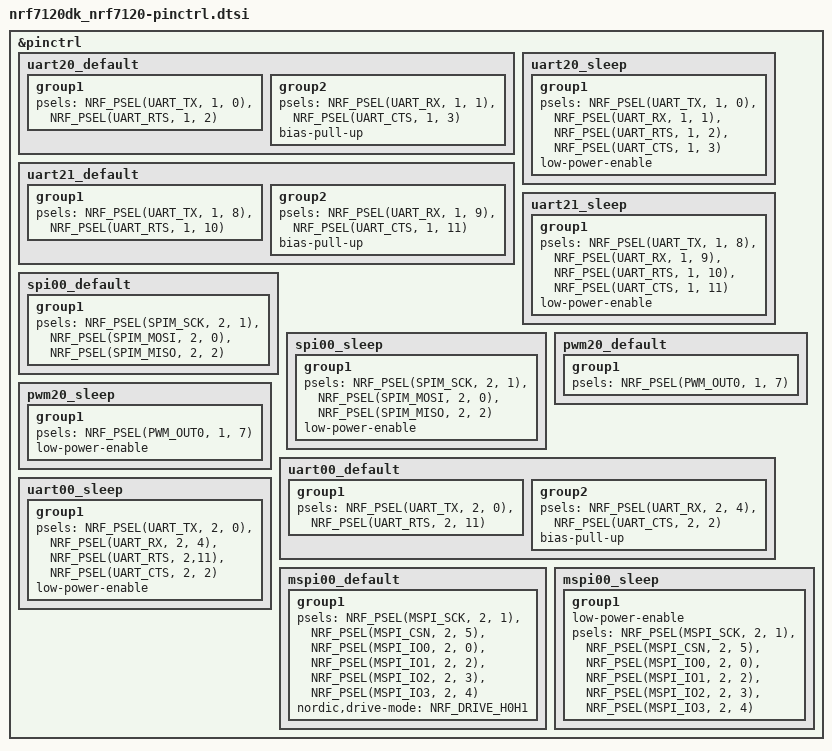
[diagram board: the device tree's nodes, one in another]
/*
 * Copyright (c) 2025 Nordic Semiconductor
 * SPDX-License-Identifier: Apache-2.0
 */

&pinctrl {
	/omit-if-no-ref/ uart20_default: uart20_default {
		group1 {
			psels = <NRF_PSEL(UART_TX, 1, 0)>,
				<NRF_PSEL(UART_RTS, 1, 2)>;
		};

		group2 {
			psels = <NRF_PSEL(UART_RX, 1, 1)>,
				<NRF_PSEL(UART_CTS, 1, 3)>;
			bias-pull-up;
		};
	};

	/omit-if-no-ref/ uart20_sleep: uart20_sleep {
		group1 {
			psels = <NRF_PSEL(UART_TX, 1, 0)>,
				<NRF_PSEL(UART_RX, 1, 1)>,
				<NRF_PSEL(UART_RTS, 1, 2)>,
				<NRF_PSEL(UART_CTS, 1, 3)>;
			low-power-enable;
		};
	};

	/omit-if-no-ref/ uart21_default: uart21_default {
		group1 {
			psels = <NRF_PSEL(UART_TX, 1, 8)>,
				<NRF_PSEL(UART_RTS, 1, 10)>;
		};

		group2 {
			psels = <NRF_PSEL(UART_RX, 1, 9)>,
				<NRF_PSEL(UART_CTS, 1, 11)>;
			bias-pull-up;
		};
	};

	/omit-if-no-ref/ uart21_sleep: uart21_sleep {
		group1 {
			psels = <NRF_PSEL(UART_TX, 1, 8)>,
				<NRF_PSEL(UART_RX, 1, 9)>,
				<NRF_PSEL(UART_RTS, 1, 10)>,
				<NRF_PSEL(UART_CTS, 1, 11)>;
			low-power-enable;
		};
	};

	/omit-if-no-ref/ spi00_default: spi00_default {
		group1 {
			psels = <NRF_PSEL(SPIM_SCK, 2, 1)>,
				<NRF_PSEL(SPIM_MOSI, 2, 0)>,
				<NRF_PSEL(SPIM_MISO, 2, 2)>;
		};
	};

	/omit-if-no-ref/ spi00_sleep: spi00_sleep {
		group1 {
			psels = <NRF_PSEL(SPIM_SCK, 2, 1)>,
				<NRF_PSEL(SPIM_MOSI, 2, 0)>,
				<NRF_PSEL(SPIM_MISO, 2, 2)>;
			low-power-enable;
		};
	};

	/omit-if-no-ref/ pwm20_default: pwm20_default {
		group1 {
			psels = <NRF_PSEL(PWM_OUT0, 1, 7)>;
		};
	};

	/omit-if-no-ref/ pwm20_sleep: pwm20_sleep {
		group1 {
			psels = <NRF_PSEL(PWM_OUT0, 1, 7)>;
			low-power-enable;
		};
	};

	/omit-if-no-ref/ uart00_default: uart00_default {
		group1 {
			psels = <NRF_PSEL(UART_TX, 2, 0)>,
				<NRF_PSEL(UART_RTS, 2, 11)>;
		};

		group2 {
			psels = <NRF_PSEL(UART_RX, 2, 4)>,
				<NRF_PSEL(UART_CTS, 2, 2)>;
			bias-pull-up;
		};
	};

	/omit-if-no-ref/ uart00_sleep: uart00_sleep {
		group1 {
			psels = <NRF_PSEL(UART_TX, 2, 0)>,
				<NRF_PSEL(UART_RX, 2, 4)>,
				<NRF_PSEL(UART_RTS, 2,11)>,
				<NRF_PSEL(UART_CTS, 2, 2)>;
			low-power-enable;
		};
	};

	/omit-if-no-ref/ mspi00_default: mspi00_default {
		group1 {
			psels = <NRF_PSEL(MSPI_SCK, 2, 1)>,
				<NRF_PSEL(MSPI_CSN, 2, 5)>,
				<NRF_PSEL(MSPI_IO0, 2, 0)>,
				<NRF_PSEL(MSPI_IO1, 2, 2)>,
				<NRF_PSEL(MSPI_IO2, 2, 3)>,
				<NRF_PSEL(MSPI_IO3, 2, 4)>;
			nordic,drive-mode = <NRF_DRIVE_H0H1>;
		};
	};

	/omit-if-no-ref/ mspi00_sleep: mspi00_sleep {
		group1 {
			low-power-enable;
			psels = <NRF_PSEL(MSPI_SCK, 2, 1)>,
				<NRF_PSEL(MSPI_CSN, 2, 5)>,
				<NRF_PSEL(MSPI_IO0, 2, 0)>,
				<NRF_PSEL(MSPI_IO1, 2, 2)>,
				<NRF_PSEL(MSPI_IO2, 2, 3)>,
				<NRF_PSEL(MSPI_IO3, 2, 4)>;
		};
	};
};
